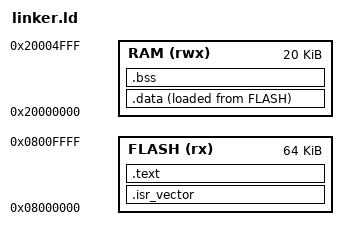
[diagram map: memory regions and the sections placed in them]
ENTRY(Reset_Handler)

MEMORY
{
    FLASH (rx) : ORIGIN = 0x08000000, LENGTH = 64K
    RAM  (rwx) : ORIGIN = 0x20000000, LENGTH = 20K
}

_estack = ORIGIN(RAM) + LENGTH(RAM);

SECTIONS
{
    .isr_vector :
    {
        KEEP(*(.isr_vector))
        . = ALIGN(4);
    } > FLASH

    .text . :   /* 显式从当前地址开始，确保紧接向量表 */
    {
        *(.text*)
        *(.rodata*)
        . = ALIGN(4);
    } > FLASH

    _sidata = LOADADDR(.data);

    .data :
    {
        . = ALIGN(4);
        _sdata = .;
        *(.data*)
        . = ALIGN(4);
        _edata = .;
    } > RAM AT > FLASH

    .bss (NOLOAD) :
    {
        . = ALIGN(4);
        _sbss = .;
        *(.bss*)
        *(COMMON)
        . = ALIGN(4);
        _ebss = .;
    } > RAM
}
